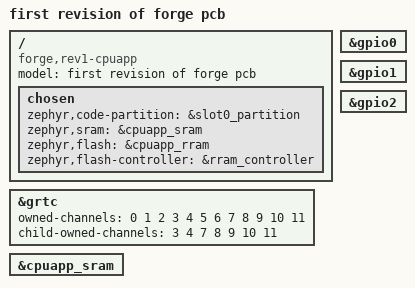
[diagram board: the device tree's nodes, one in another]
/dts-v1/;
#include <nordic/nrf54l15_cpuapp.dtsi>
#include "rev1-pinctrl.dtsi"

/ {
	model = "first revision of forge pcb";
	compatible = "forge,rev1-cpuapp";

	chosen {
		zephyr,code-partition = &slot0_partition;
		zephyr,sram = &cpuapp_sram;
		zephyr,flash = &cpuapp_rram;
		zephyr,flash-controller = &rram_controller;
	};
};

&grtc {
	owned-channels = <0 1 2 3 4 5 6 7 8 9 10 11>;
	/* Channels 7-11 reserved for Zero Latency IRQs, 3-4 for FLPR */
	child-owned-channels = <3 4 7 8 9 10 11>;
	status = "okay";
};

&cpuapp_sram {
	status = "okay";
};

#include <nordic/nrf54l15_partition.dtsi>

&gpio0 {
    status = "okay";
};

&gpio1 {
    status = "okay";
};

&gpio2 {
    status = "okay";
};
